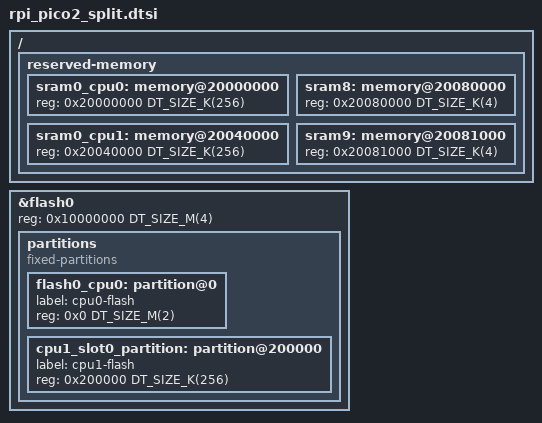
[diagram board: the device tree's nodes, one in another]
/*
 * Copyright (c) 2025 Dmitrii Sharshakov <d3dx12.xx@gmail.com>
 *
 * SPDX-License-Identifier: Apache-2.0
 */

#include <mem.h>

&flash0 {
	status = "okay";
	reg = <0x10000000 DT_SIZE_M(4)>;

	partitions {
		compatible = "fixed-partitions";
		#address-cells = <0x1>;
		#size-cells = <0x1>;

		flash0_cpu0: partition@0 {
			label = "cpu0-flash";
			reg = <0x0 DT_SIZE_M(2)>;
		};

		cpu1_slot0_partition: partition@200000 {
			label = "cpu1-flash";
			reg = <0x200000 DT_SIZE_K(256)>;
		};
	};
};

/ {
	reserved-memory {
		#address-cells = <1>;
		#size-cells = <1>;
		ranges;

		/* CPU0 */
		sram0_cpu0: memory@20000000 {
			reg = <0x20000000 DT_SIZE_K(256)>;
		};

		/* CPU1 */
		sram0_cpu1: memory@20040000 {
			reg = <0x20040000 DT_SIZE_K(256)>;
		};

		/* Shared and directly mapped */
		sram8: memory@20080000 {
			reg = <0x20080000 DT_SIZE_K(4)>;
		};
		sram9: memory@20081000 {
			reg = <0x20081000 DT_SIZE_K(4)>;
		};
	};
};
